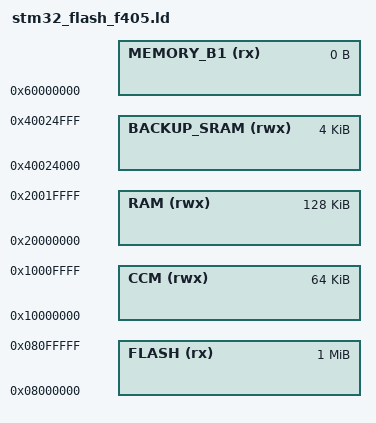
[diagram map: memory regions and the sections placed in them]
/*
*****************************************************************************
**
**  File        : stm32_flash_f405.ld
**
**  Abstract    : Linker script for STM32F405RG Device with
**                1024KByte FLASH, 128KByte RAM 64KByte CCM (RAM)
**
*****************************************************************************
*/

/* Entry Point */
ENTRY(Reset_Handler)

/* Specify the memory areas */
MEMORY
{
    FLASH (rx)        : ORIGIN = 0x08000000, LENGTH = 1M
    RAM (rwx)         : ORIGIN = 0x20000000, LENGTH = 128K
    CCM (rwx)         : ORIGIN = 0x10000000, LENGTH = 64K
    BACKUP_SRAM (rwx) : ORIGIN = 0x40024000, LENGTH = 4K
    MEMORY_B1 (rx)    : ORIGIN = 0x60000000, LENGTH = 0K
}
/* note CCM could be used for stack */

INCLUDE "stm32_flash.ld"
